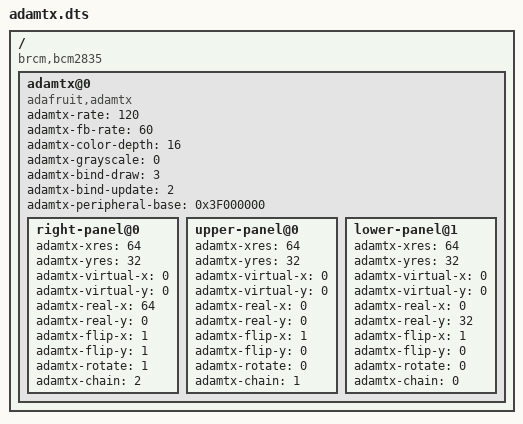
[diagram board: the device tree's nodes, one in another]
/dts-v1/;
/plugin/;

/ {
        compatible = "brcm,bcm2835", "brcm,bcm2708", "brcm,bcm2709";

        fragment@0 {
                target-path = "/";
                __overlay__ {
                        adamtx@0 {
                                status = "okay";
                                compatible = "adafruit,adamtx";
                                adamtx-rate = <120>;
                                adamtx-fb-rate = <60>;
                                adamtx-color-depth = <16>;
                                adamtx-grayscale = <0>;
                                adamtx-bind-draw = <3>;
                                adamtx-bind-update = <2>;
                                adamtx-peripheral-base = <0x3F000000>;

                                right-panel@0 {
                                        adamtx-xres = <64>;
                                        adamtx-yres = <32>;
                                        adamtx-virtual-x = <0>;
                                        adamtx-virtual-y = <0>;
                                        adamtx-real-x = <64>;
                                        adamtx-real-y = <0>;
                                        adamtx-flip-x = <1>;
                                        adamtx-flip-y = <1>;
                                        adamtx-rotate = <1>;
                                        adamtx-chain = <2>;
                                };
                                upper-panel@0 {
                                        adamtx-xres = <64>;
                                        adamtx-yres = <32>;
                                        adamtx-virtual-x = <0>;
                                        adamtx-virtual-y = <0>;
                                        adamtx-real-x = <0>;
                                        adamtx-real-y = <0>;
                                        adamtx-flip-x = <1>;
                                        adamtx-flip-y = <0>;
                                        adamtx-rotate = <0>;
                                        adamtx-chain = <1>;
                                };
                                lower-panel@1 {
                                        adamtx-xres = <64>;
                                        adamtx-yres = <32>;
                                        adamtx-virtual-x = <0>;
                                        adamtx-virtual-y = <0>;
                                        adamtx-real-x = <0>;
                                        adamtx-real-y = <32>;
                                        adamtx-flip-x = <1>;
                                        adamtx-flip-y = <0>;
                                        adamtx-rotate = <0>;
                                        adamtx-chain = <0>;
                                };
                        };
                };
        };
};
